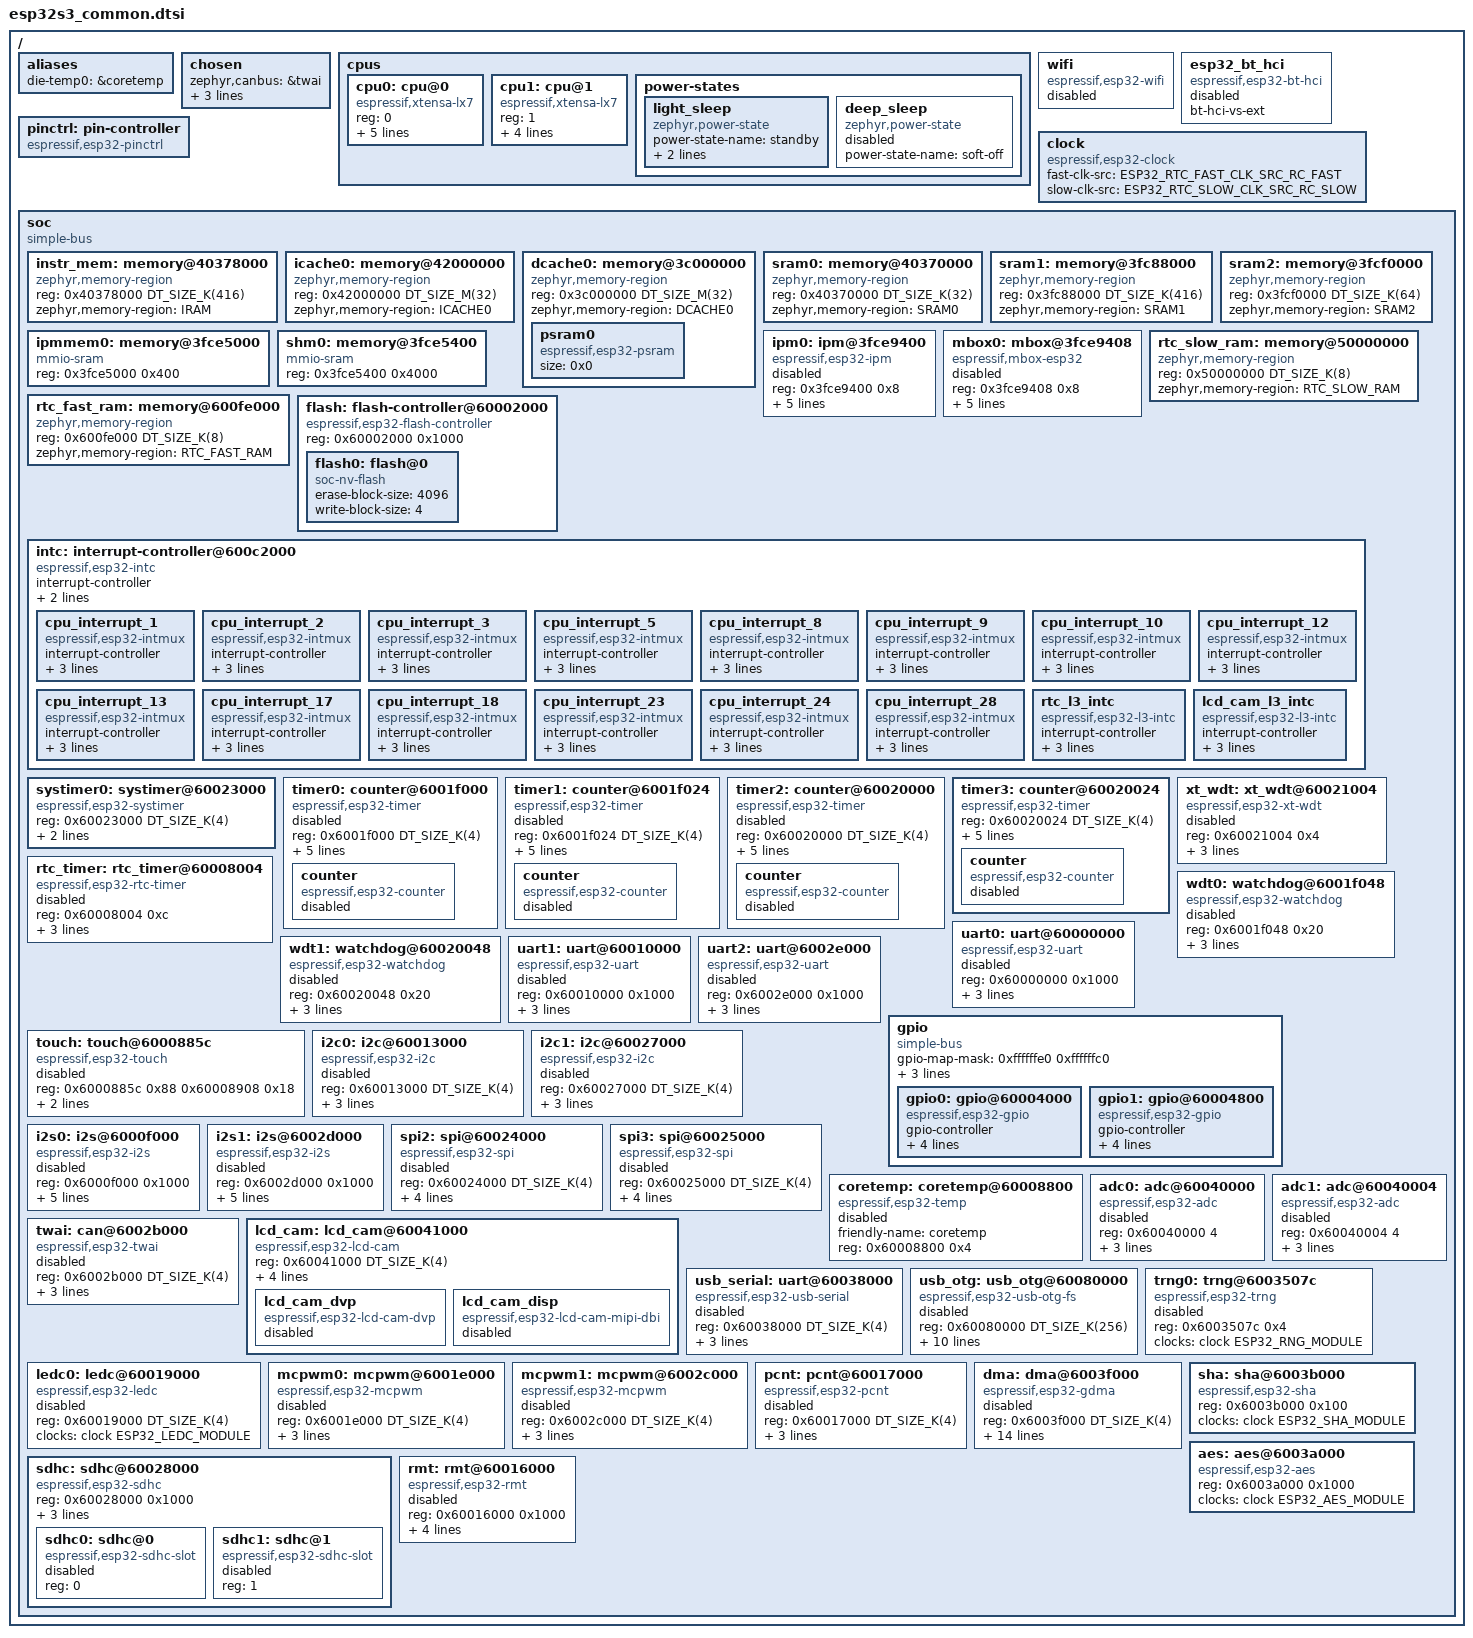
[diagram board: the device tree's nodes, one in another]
/*
 * Copyright (c) 2022-2025 Espressif Systems (Shanghai) Co., Ltd.
 *
 * SPDX-License-Identifier: Apache-2.0
 */
#include <mem.h>
#include <freq.h>
#include <xtensa/xtensa.dtsi>
#include <zephyr/dt-bindings/adc/adc.h>
#include <zephyr/dt-bindings/gpio/gpio.h>
#include <zephyr/dt-bindings/i2c/i2c.h>
#include <zephyr/dt-bindings/clock/esp32s3_clock.h>
#include <zephyr/dt-bindings/interrupt-controller/espressif-esp32s3-intmux.h>
#include <zephyr/dt-bindings/pinctrl/esp32s3-pinctrl.h>

/ {
	aliases {
		die-temp0 = &coretemp;
	};

	chosen {
		zephyr,canbus = &twai;
		zephyr,entropy = &trng0;
		zephyr,flash-controller = &flash;
		zephyr,bt-hci = &esp32_bt_hci;
	};

	cpus {
		#address-cells = <1>;
		#size-cells = <0>;

		cpu0: cpu@0 {
			device_type = "cpu";
			compatible = "espressif,xtensa-lx7";
			reg = <0>;
			cpu-power-states = <&light_sleep &deep_sleep>;
			clock-source = <ESP32_CPU_CLK_SRC_PLL>;
			clock-frequency = <DT_FREQ_M(240)>;
			xtal-freq = <DT_FREQ_M(40)>;
			d-cache-line-size = <16>;
		};

		cpu1: cpu@1 {
			device_type = "cpu";
			compatible = "espressif,xtensa-lx7";
			reg = <1>;
			clock-source = <ESP32_CPU_CLK_SRC_PLL>;
			clock-frequency = <DT_FREQ_M(240)>;
			xtal-freq = <DT_FREQ_M(40)>;
			d-cache-line-size = <16>;
		};

		power-states {
			light_sleep: light_sleep {
				compatible = "zephyr,power-state";
				power-state-name = "standby";
				min-residency-us = <1000>;
				exit-latency-us = <0>;
			};

			deep_sleep: deep_sleep {
				/* Deep sleep must be entered using pm_state_force()
				 * or sys_poweroff() calls only
				 */
				compatible = "zephyr,power-state";
				power-state-name = "soft-off";
				status = "disabled";
			};
		};
	};

	wifi: wifi {
		compatible = "espressif,esp32-wifi";
		status = "disabled";
	};

	esp32_bt_hci: esp32_bt_hci {
		compatible = "espressif,esp32-bt-hci";
		bt-hci-vs-ext;
		status = "disabled";
	};

	pinctrl: pin-controller {
		compatible = "espressif,esp32-pinctrl";
		status = "okay";
	};

	clock: clock {
		compatible = "espressif,esp32-clock";
		fast-clk-src = <ESP32_RTC_FAST_CLK_SRC_RC_FAST>;
		slow-clk-src = <ESP32_RTC_SLOW_CLK_SRC_RC_SLOW>;
		#clock-cells = <1>;
		status = "okay";
	};

	soc {
		#address-cells = <1>;
		#size-cells = <1>;
		compatible = "simple-bus";
		ranges;

		instr_mem: memory@40378000 {
			compatible = "zephyr,memory-region";
			reg = <0x40378000 DT_SIZE_K(416)>;
			zephyr,memory-region = "IRAM";
		};

		icache0: memory@42000000 {
			compatible = "zephyr,memory-region";
			reg = <0x42000000 DT_SIZE_M(32)>;
			zephyr,memory-region = "ICACHE0";
		};

		dcache0: memory@3c000000 {
			compatible = "zephyr,memory-region";
			reg = <0x3c000000 DT_SIZE_M(32)>;
			zephyr,memory-region = "DCACHE0";

			psram0: psram0 {
				compatible = "espressif,esp32-psram";
				size = <0x0>;
			};
		};

		sram0: memory@40370000 {
			compatible = "zephyr,memory-region", "mmio-sram";
			reg = <0x40370000 DT_SIZE_K(32)>;
			zephyr,memory-region = "SRAM0";
		};

		sram1: memory@3fc88000 {
			compatible = "zephyr,memory-region", "mmio-sram";
			reg = <0x3fc88000 DT_SIZE_K(416)>;
			zephyr,memory-region = "SRAM1";
		};

		sram2: memory@3fcf0000 {
			compatible = "zephyr,memory-region", "mmio-sram";
			reg = <0x3fcf0000 DT_SIZE_K(64)>;
			zephyr,memory-region = "SRAM2";
		};

		ipmmem0: memory@3fce5000 {
			compatible = "mmio-sram";
			reg = <0x3fce5000 0x400>;
		};

		shm0: memory@3fce5400 {
			compatible = "mmio-sram";
			reg = <0x3fce5400 0x4000>;
		};

		ipm0: ipm@3fce9400 {
			compatible = "espressif,esp32-ipm";
			reg = <0x3fce9400 0x8>;
			status = "disabled";
			shared-memory = <&ipmmem0>;
			shared-memory-size = <0x400>;
			interrupt-parent = <&cpu_interrupt_28>;
			interrupts = <FROM_CPU_INTR0_SOURCE>, <FROM_CPU_INTR1_SOURCE>;
		};

		mbox0: mbox@3fce9408 {
			compatible = "espressif,mbox-esp32";
			reg = <0x3fce9408 0x8>;
			status = "disabled";
			shared-memory = <&ipmmem0>;
			shared-memory-size = <0x400>;
			interrupt-parent = <&cpu_interrupt_28>;
			interrupts = <FROM_CPU_INTR0_SOURCE>,<FROM_CPU_INTR1_SOURCE>;
			#mbox-cells = <1>;
		};

		rtc_slow_ram: memory@50000000 {
			compatible = "zephyr,memory-region", "mmio-sram";
			reg = <0x50000000 DT_SIZE_K(8)>;
			zephyr,memory-region = "RTC_SLOW_RAM";
		};

		rtc_fast_ram: memory@600fe000 {
			compatible = "zephyr,memory-region", "mmio-sram";
			reg = <0x600fe000 DT_SIZE_K(8)>;
			zephyr,memory-region = "RTC_FAST_RAM";
		};

		flash: flash-controller@60002000 {
			compatible = "espressif,esp32-flash-controller";
			reg = <0x60002000 0x1000>;
			#address-cells = <1>;
			#size-cells = <1>;
			ranges;

			flash0: flash@0 {
				compatible = "soc-nv-flash";
				erase-block-size = <4096>;
				write-block-size = <4>;
				#address-cells = <1>;
				#size-cells = <1>;
				/* reg and ranges are specified in SOC/SIP dtsi */
			};
		};

		intc: interrupt-controller@600c2000 {
			compatible = "espressif,esp32-intc";
			#interrupt-cells = <3>;
			#address-cells = <0>;
			interrupt-controller;
			/* INTMUX MAP base and pending STATUS base
			 * [core0_map, core0_stat, core1_map, core1_stat] */
			reg = <0x600c2000 0x1000>, <0x600c218c 0x10>,
			      <0x600c2800 0x1000>, <0x600c298c 0x10>;
			reg-names = "map0", "status0", "map1", "status1";
			status = "okay";

			cpu_interrupt_1: cpu_interrupt_1 {
				compatible = "espressif,esp32-intmux";
				interrupt-controller;
				#interrupt-cells = <1>;
				interrupt-parent = <&intc>;
				interrupts = <ESP_CPU_IRQ_L1_LVL_1 IRQ_DEFAULT_PRIORITY 0>;
			};

			cpu_interrupt_2: cpu_interrupt_2 {
				compatible = "espressif,esp32-intmux";
				interrupt-controller;
				#interrupt-cells = <1>;
				interrupt-parent = <&intc>;
				interrupts = <ESP_CPU_IRQ_L1_LVL_2 IRQ_DEFAULT_PRIORITY 0>;
			};

			cpu_interrupt_3: cpu_interrupt_3 {
				compatible = "espressif,esp32-intmux";
				interrupt-controller;
				#interrupt-cells = <1>;
				interrupt-parent = <&intc>;
				interrupts = <ESP_CPU_IRQ_L1_LVL_3 IRQ_DEFAULT_PRIORITY 0>;
			};

			cpu_interrupt_5: cpu_interrupt_5 {
				compatible = "espressif,esp32-intmux";
				interrupt-controller;
				#interrupt-cells = <1>;
				interrupt-parent = <&intc>;
				interrupts = <ESP_CPU_IRQ_L1_LVL_5 IRQ_DEFAULT_PRIORITY 0>;
			};

			cpu_interrupt_8: cpu_interrupt_8 {
				compatible = "espressif,esp32-intmux";
				interrupt-controller;
				#interrupt-cells = <1>;
				interrupt-parent = <&intc>;
				interrupts = <ESP_CPU_IRQ_L1_LVL_8 IRQ_DEFAULT_PRIORITY 0>;
			};

			cpu_interrupt_9: cpu_interrupt_9 {
				compatible = "espressif,esp32-intmux";
				interrupt-controller;
				#interrupt-cells = <1>;
				interrupt-parent = <&intc>;
				interrupts = <ESP_CPU_IRQ_L1_LVL_9 IRQ_DEFAULT_PRIORITY 0>;
			};

			cpu_interrupt_10: cpu_interrupt_10 {
				compatible = "espressif,esp32-intmux";
				interrupt-controller;
				#interrupt-cells = <1>;
				interrupt-parent = <&intc>;
				interrupts = <ESP_CPU_IRQ_L1_EDG_10 IRQ_DEFAULT_PRIORITY 0>;
			};

			cpu_interrupt_12: cpu_interrupt_12 {
				compatible = "espressif,esp32-intmux";
				interrupt-controller;
				#interrupt-cells = <1>;
				interrupt-parent = <&intc>;
				interrupts = <ESP_CPU_IRQ_L1_LVL_12 IRQ_DEFAULT_PRIORITY
					      (ESP_INTR_FLAG_SHARED | ESP_INTR_FLAG_IRAM)>;
			};

			cpu_interrupt_13: cpu_interrupt_13 {
				compatible = "espressif,esp32-intmux";
				interrupt-controller;
				#interrupt-cells = <1>;
				interrupt-parent = <&intc>;
				interrupts = <ESP_CPU_IRQ_L1_LVL_13 IRQ_DEFAULT_PRIORITY 0>;
			};

			cpu_interrupt_17: cpu_interrupt_17 {
				compatible = "espressif,esp32-intmux";
				interrupt-controller;
				#interrupt-cells = <1>;
				interrupt-parent = <&intc>;
				interrupts = <ESP_CPU_IRQ_L1_LVL_17 IRQ_DEFAULT_PRIORITY 0>;
			};

			cpu_interrupt_18: cpu_interrupt_18 {
				compatible = "espressif,esp32-intmux";
				interrupt-controller;
				#interrupt-cells = <1>;
				interrupt-parent = <&intc>;
				interrupts = <ESP_CPU_IRQ_L1_LVL_18 IRQ_DEFAULT_PRIORITY 0>;
			};

			/*
			 * Reserved for the BLE controller, which claims its source
			 * at runtime. It has no devicetree consumer, but the node
			 * must exist: it is what gives the line an intc_table entry
			 * for the dispatcher that esp_intc_intr_enable() installs.
			 */
			cpu_interrupt_23: cpu_interrupt_23 {
				compatible = "espressif,esp32-intmux";
				interrupt-controller;
				#interrupt-cells = <1>;
				interrupt-parent = <&intc>;
				interrupts = <ESP_CPU_IRQ_L3_LVL_23 IRQ_DEFAULT_PRIORITY 0>;
			};

			cpu_interrupt_24: cpu_interrupt_24 {
				compatible = "espressif,esp32-intmux";
				interrupt-controller;
				#interrupt-cells = <1>;
				interrupt-parent = <&intc>;
				interrupts = <ESP_CPU_IRQ_L4_LVL_24 IRQ_DEFAULT_PRIORITY 0>;
			};

			cpu_interrupt_28: cpu_interrupt_28 {
				compatible = "espressif,esp32-intmux";
				interrupt-controller;
				#interrupt-cells = <1>;
				interrupt-parent = <&intc>;
				interrupts = <ESP_CPU_IRQ_L4_EDG_28 IRQ_DEFAULT_PRIORITY 0>;
			};

			/* Level-3 aggregators
			 */

			rtc_l3_intc: rtc_l3_intc {
				compatible = "espressif,esp32-l3-intc";
				interrupt-controller;
				#interrupt-cells = <1>;
				interrupt-parent = <&cpu_interrupt_1>;
				interrupts = <RTC_CORE_INTR_SOURCE>;
				status-reg = <0x60008048>;
			};

			lcd_cam_l3_intc: lcd_cam_l3_intc {
				compatible = "espressif,esp32-l3-intc";
				interrupt-controller;
				#interrupt-cells = <1>;
				interrupt-parent = <&cpu_interrupt_17>;
				interrupts = <LCD_CAM_INTR_SOURCE>;
				status-reg = <0x6004106c>;
			};
		};

		systimer0: systimer@60023000 {
			compatible = "espressif,esp32-systimer";
			reg = <0x60023000 DT_SIZE_K(4)>;

			interrupt-parent = <&cpu_interrupt_10>;
			interrupts = <SYSTIMER_TARGET2_EDGE_INTR_SOURCE>;
			status = "okay";
		};

		timer0: counter@6001f000 {
			compatible = "espressif,esp32-timer";
			reg = <0x6001f000 DT_SIZE_K(4)>;
			clocks = <&clock ESP32_TIMG0_MODULE>;
			group = <0>;
			index = <0>;
			interrupt-parent = <&cpu_interrupt_8>;
			interrupts = <TG0_T0_LEVEL_INTR_SOURCE>;
			status = "disabled";

			counter {
				compatible = "espressif,esp32-counter";
				status = "disabled";
			};
		};

		timer1: counter@6001f024 {
			compatible = "espressif,esp32-timer";
			reg = <0x6001f024 DT_SIZE_K(4)>;
			clocks = <&clock ESP32_TIMG0_MODULE>;
			group = <0>;
			index = <1>;
			interrupt-parent = <&cpu_interrupt_8>;
			interrupts = <TG0_T1_LEVEL_INTR_SOURCE>;
			status = "disabled";

			counter {
				compatible = "espressif,esp32-counter";
				status = "disabled";
			};
		};

		timer2: counter@60020000 {
			compatible = "espressif,esp32-timer";
			reg = <0x60020000 DT_SIZE_K(4)>;
			clocks = <&clock ESP32_TIMG1_MODULE>;
			group = <1>;
			index = <0>;
			interrupt-parent = <&cpu_interrupt_8>;
			interrupts = <TG1_T0_LEVEL_INTR_SOURCE>;
			status = "disabled";

			counter {
				compatible = "espressif,esp32-counter";
				status = "disabled";
			};
		};

		timer3: counter@60020024 {
			compatible = "espressif,esp32-timer";
			reg = <0x60020024 DT_SIZE_K(4)>;
			clocks = <&clock ESP32_TIMG1_MODULE>;
			group = <1>;
			index = <1>;
			interrupt-parent = <&cpu_interrupt_8>;
			interrupts = <TG1_T1_LEVEL_INTR_SOURCE>;

			counter {
				compatible = "espressif,esp32-counter";
				status = "disabled";
			};
		};

		xt_wdt: xt_wdt@60021004 {
			compatible = "espressif,esp32-xt-wdt";
			reg = <0x60021004 0x4>;
			clocks = <&clock ESP32_MODULE_MAX>;
			interrupt-parent = <&rtc_l3_intc>;
			interrupts = <16>;	/* RTC_CNTL_XTAL32K_DEAD */
			status = "disabled";
		};

		rtc_timer: rtc_timer@60008004 {
			reg = <0x60008004 0xc>;
			compatible = "espressif,esp32-rtc-timer";
			clocks = <&clock ESP32_MODULE_MAX>;
			interrupt-parent = <&rtc_l3_intc>;
			interrupts = <10>;	/* RTC_CNTL_MAIN_TIMER */
			status = "disabled";
		};

		wdt0: watchdog@6001f048 {
			compatible = "espressif,esp32-watchdog";
			reg = <0x6001f048 0x20>;
			interrupt-parent = <&cpu_interrupt_8>;
			interrupts = <TG0_WDT_LEVEL_INTR_SOURCE>;
			clocks = <&clock ESP32_TIMG0_MODULE>;
			status = "disabled";
		};

		wdt1: watchdog@60020048 {
			compatible = "espressif,esp32-watchdog";
			reg = <0x60020048 0x20>;
			interrupt-parent = <&cpu_interrupt_24>;
			interrupts = <TG1_WDT_LEVEL_INTR_SOURCE>;
			clocks = <&clock ESP32_TIMG1_MODULE>;
			status = "disabled";
		};

		uart0: uart@60000000 {
			compatible = "espressif,esp32-uart";
			reg = <0x60000000 0x1000>;
			interrupt-parent = <&cpu_interrupt_5>;
			interrupts = <UART0_INTR_SOURCE>;
			clocks = <&clock ESP32_UART0_MODULE>;
			status = "disabled";
		};

		uart1: uart@60010000 {
			compatible = "espressif,esp32-uart";
			reg = <0x60010000 0x1000>;
			interrupt-parent = <&cpu_interrupt_5>;
			interrupts = <UART1_INTR_SOURCE>;
			clocks = <&clock ESP32_UART1_MODULE>;
			status = "disabled";
		};

		uart2: uart@6002e000 {
			compatible = "espressif,esp32-uart";
			reg = <0x6002e000 0x1000>;
			interrupt-parent = <&cpu_interrupt_5>;
			interrupts = <UART2_INTR_SOURCE>;
			clocks = <&clock ESP32_UART2_MODULE>;
			status = "disabled";
		};

		gpio: gpio {
			compatible = "simple-bus";
			gpio-map-mask = <0xffffffe0 0xffffffc0>;
			gpio-map-pass-thru = <0x1f 0x3f>;
			gpio-map = <0x00 0x0 &gpio0 0x0 0x0
				    0x20 0x0 &gpio1 0x0 0x0>;
			#gpio-cells = <2>;
			#address-cells = <1>;
			#size-cells = <1>;
			ranges;

			gpio0: gpio@60004000 {
				compatible = "espressif,esp32-gpio";
				gpio-controller;
				#gpio-cells = <2>;
				reg = <0x60004000 0x800>;
				interrupt-parent = <&cpu_interrupt_3>;
				interrupts = <GPIO_INTR_SOURCE>;
				/* Maximum available pins (per port)
				 * Actual occupied pins are specified
				 * on part number dtsi level, using
				 * the `gpio-reserved-ranges` property.
				 */
				ngpios = <32>;  /* 0..31 */
			};

			gpio1: gpio@60004800 {
				compatible = "espressif,esp32-gpio";
				gpio-controller;
				#gpio-cells = <2>;
				reg = <0x60004800 0x800>;
				interrupt-parent = <&cpu_interrupt_3>;
				interrupts = <GPIO_INTR_SOURCE>;
				ngpios = <22>; /* 32..53 */
			};
		};

		touch: touch@6000885c {
			compatible = "espressif,esp32-touch";
			reg = <0x6000885c 0x88 0x60008908 0x18>;
			interrupt-parent = <&rtc_l3_intc>;
			interrupts = <4>,	/* RTC_CNTL_TOUCH_SCAN_DONE */
				     <6>,	/* RTC_CNTL_TOUCH_DONE      */
				     <7>,	/* RTC_CNTL_TOUCH_ACTIVE    */
				     <8>,	/* RTC_CNTL_TOUCH_INACTIVE  */
				     <18>;	/* RTC_CNTL_TOUCH_TIMEOUT   */
			status = "disabled";
		};

		i2c0: i2c@60013000 {
			compatible = "espressif,esp32-i2c";
			#address-cells = <1>;
			#size-cells = <0>;
			reg = <0x60013000 DT_SIZE_K(4)>;
			interrupt-parent = <&cpu_interrupt_17>;
			interrupts = <I2C_EXT0_INTR_SOURCE>;
			clocks = <&clock ESP32_I2C0_MODULE>;
			status = "disabled";
		};

		i2c1: i2c@60027000 {
			compatible = "espressif,esp32-i2c";
			#address-cells = <1>;
			#size-cells = <0>;
			reg = <0x60027000 DT_SIZE_K(4)>;
			interrupt-parent = <&cpu_interrupt_17>;
			interrupts = <I2C_EXT1_INTR_SOURCE>;
			clocks = <&clock ESP32_I2C1_MODULE>;
			status = "disabled";
		};

		i2s0: i2s@6000f000 {
			compatible = "espressif,esp32-i2s";
			#address-cells = <1>;
			#size-cells = <0>;
			reg = <0x6000f000 0x1000>;
			interrupt-parent = <&cpu_interrupt_17>;
			interrupts = <I2S0_INTR_SOURCE>;
			clocks = <&clock ESP32_I2S0_MODULE>;
			dmas = <&dma 2>, <&dma 3>;
			dma-names = "rx", "tx";
			unit = <0>;
			status = "disabled";
		};

		i2s1: i2s@6002d000 {
			compatible = "espressif,esp32-i2s";
			#address-cells = <1>;
			#size-cells = <0>;
			reg = <0x6002d000 0x1000>;
			interrupt-parent = <&cpu_interrupt_17>;
			interrupts = <I2S1_INTR_SOURCE>;
			clocks = <&clock ESP32_I2S1_MODULE>;
			dmas = <&dma 4>, <&dma 5>;
			dma-names = "rx", "tx";
			unit = <1>;
			status = "disabled";
		};

		spi2: spi@60024000 {
			compatible = "espressif,esp32-spi";
			reg = <0x60024000 DT_SIZE_K(4)>;
			interrupt-parent = <&cpu_interrupt_17>;
			interrupts = <SPI2_INTR_SOURCE>;
			clocks = <&clock ESP32_SPI2_MODULE>;
			dma-host = <0>;
			status = "disabled";
		};

		spi3: spi@60025000 {
			compatible = "espressif,esp32-spi";
			reg = <0x60025000 DT_SIZE_K(4)>;
			interrupt-parent = <&cpu_interrupt_13>;
			interrupts = <SPI3_INTR_SOURCE>;
			clocks = <&clock ESP32_SPI3_MODULE>;
			dma-host = <1>;
			status = "disabled";
		};

		coretemp: coretemp@60008800 {
			compatible = "espressif,esp32-temp";
			friendly-name = "coretemp";
			reg = <0x60008800 0x4>;
			status = "disabled";
		};

		adc0: adc@60040000 {
			compatible = "espressif,esp32-adc";
			reg = <0x60040000 4>;
			clocks = <&clock ESP32_SARADC_MODULE>;
			unit = <1>;
			channel-count = <10>;
			#io-channel-cells = <1>;
			status = "disabled";
		};

		adc1: adc@60040004 {
			compatible = "espressif,esp32-adc";
			reg = <0x60040004 4>;
			clocks = <&clock ESP32_SARADC_MODULE>;
			unit = <2>;
			channel-count = <10>;
			#io-channel-cells = <1>;
			status = "disabled";
		};

		twai: can@6002b000 {
			compatible = "espressif,esp32-twai";
			reg = <0x6002b000 DT_SIZE_K(4)>;
			interrupt-parent = <&cpu_interrupt_17>;
			interrupts = <TWAI_INTR_SOURCE>;
			clocks = <&clock ESP32_TWAI_MODULE>;
			status = "disabled";
		};

		lcd_cam: lcd_cam@60041000 {
			compatible = "espressif,esp32-lcd-cam";
			reg = <0x60041000 DT_SIZE_K(4)>;
			clocks = <&clock ESP32_LCD_CAM_MODULE>;
			/*
			 * Level-3 leaves: each cell is the flag's raw bit position in
			 * the aggregator's status-reg, so irq_enable(DT_IRQN_BY_IDX(
			 * lcd_cam, n)) targets bit n. Their OR is the aggregator's
			 * mask, and they get four consecutive slots in the 3rd-level
			 * ISR-table window.
			 */
			interrupt-parent = <&lcd_cam_l3_intc>;
			interrupts = <0>,	/* LCD_VSYNC      */
				     <1>,	/* LCD_TRANS_DONE */
				     <2>,	/* CAM_VSYNC      */
				     <3>;	/* CAM_HS         */
			dmas = <&dma 6>, <&dma 7>;
			dma-names = "rx", "tx";

			lcd_cam_dvp: lcd_cam_dvp {
				compatible = "espressif,esp32-lcd-cam-dvp";
				status = "disabled";
			};

			lcd_cam_disp: lcd_cam_disp {
				compatible = "espressif,esp32-lcd-cam-mipi-dbi";
				#address-cells = <1>;
				#size-cells = <0>;
				status = "disabled";
			};
		};

		usb_serial: uart@60038000 {
			compatible = "espressif,esp32-usb-serial";
			reg = <0x60038000 DT_SIZE_K(4)>;
			status = "disabled";
			interrupt-parent = <&cpu_interrupt_2>;
			interrupts = <USB_SERIAL_JTAG_INTR_SOURCE>;
			clocks = <&clock ESP32_USB_MODULE>;
		};

		usb_otg: usb_otg@60080000 {
			compatible = "espressif,esp32-usb-otg-fs", "snps,dwc2";
			reg = <0x60080000 DT_SIZE_K(256)>;
			status = "disabled";
			interrupt-parent = <&cpu_interrupt_18>;
			interrupts = <USB_INTR_SOURCE>;
			clocks = <&clock ESP32_USB_MODULE>;
			num-out-eps = <6>;
			num-in-eps = <6>;
			ghwcfg1 = <0x00000000>;
			ghwcfg2 = <0x224dd930>;
			ghwcfg4 = <0xd3f0a030>;
			phy-dp-pin = <20>;
			phy-dm-pin = <19>;
		};

		trng0: trng@6003507c {
			compatible = "espressif,esp32-trng";
			reg = <0x6003507c 0x4>;
			clocks = <&clock ESP32_RNG_MODULE>;
			status = "disabled";
		};

		ledc0: ledc@60019000 {
			compatible = "espressif,esp32-ledc";
			#pwm-cells = <3>;
			reg = <0x60019000 DT_SIZE_K(4)>;
			clocks = <&clock ESP32_LEDC_MODULE>;
			status = "disabled";
		};

		mcpwm0: mcpwm@6001e000 {
			compatible = "espressif,esp32-mcpwm";
			reg = <0x6001e000 DT_SIZE_K(4)>;
			interrupt-parent = <&cpu_interrupt_9>;
			interrupts = <PWM0_INTR_SOURCE>;
			clocks = <&clock ESP32_PWM0_MODULE>;
			#pwm-cells = <3>;
			status = "disabled";
		};

		mcpwm1: mcpwm@6002c000 {
			compatible = "espressif,esp32-mcpwm";
			reg = <0x6002c000 DT_SIZE_K(4)>;
			interrupt-parent = <&cpu_interrupt_9>;
			interrupts = <PWM1_INTR_SOURCE>;
			clocks = <&clock ESP32_PWM1_MODULE>;
			#pwm-cells = <3>;
			status = "disabled";
		};

		pcnt: pcnt@60017000 {
			compatible = "espressif,esp32-pcnt";
			reg = <0x60017000 DT_SIZE_K(4)>;
			interrupt-parent = <&cpu_interrupt_9>;
			interrupts = <PCNT_INTR_SOURCE>;
			clocks = <&clock ESP32_PCNT_MODULE>;
			status = "disabled";
		};

		dma: dma@6003f000 {
			compatible = "espressif,esp32-gdma";
			reg = <0x6003f000 DT_SIZE_K(4)>;
			#dma-cells = <1>;
			interrupt-parent = <&cpu_interrupt_12>;
			interrupts = <DMA_IN_CH0_INTR_SOURCE>,
				     <DMA_OUT_CH0_INTR_SOURCE>,
				     <DMA_IN_CH1_INTR_SOURCE>,
				     <DMA_OUT_CH1_INTR_SOURCE>,
				     <DMA_IN_CH2_INTR_SOURCE>,
				     <DMA_OUT_CH2_INTR_SOURCE>,
				     <DMA_IN_CH3_INTR_SOURCE>,
				     <DMA_OUT_CH3_INTR_SOURCE>,
				     <DMA_IN_CH4_INTR_SOURCE>,
				     <DMA_OUT_CH4_INTR_SOURCE>;
			clocks = <&clock ESP32_GDMA_MODULE>;
			dma-channels = <10>;
			dma-buf-addr-alignment = <4>;
			status = "disabled";
		};

		sdhc: sdhc@60028000 {
			compatible = "espressif,esp32-sdhc";
			reg = <0x60028000 0x1000>;
			interrupt-parent = <&cpu_interrupt_13>;
			interrupts = <SDIO_HOST_INTR_SOURCE>;
			clocks = <&clock ESP32_SDMMC_MODULE>;
			#address-cells = <1>;
			#size-cells = <0>;

			sdhc0: sdhc@0 {
				compatible = "espressif,esp32-sdhc-slot";
				reg = <0>;
				status = "disabled";
			};

			sdhc1: sdhc@1 {
				compatible = "espressif,esp32-sdhc-slot";
				reg = <1>;
				status = "disabled";
			};
		};

		sha: sha@6003b000 {
			compatible = "espressif,esp32-sha";
			reg = <0x6003b000 0x100>;
			clocks = <&clock ESP32_SHA_MODULE>;
			status = "okay";
		};

		aes: aes@6003a000 {
			compatible = "espressif,esp32-aes";
			reg = <0x6003a000 0x1000>;
			clocks = <&clock ESP32_AES_MODULE>;
			status = "okay";
		};

		rmt: rmt@60016000 {
			compatible = "espressif,esp32-rmt";
			#pulse-io-cells = <1>;
			reg = <0x60016000 0x1000>;
			interrupts = <RMT_INTR_SOURCE IRQ_DEFAULT_PRIORITY 0>;
			interrupt-parent = <&intc>;
			clocks = <&clock ESP32_RMT_MODULE>;
			status = "disabled";
		};
	};
};
